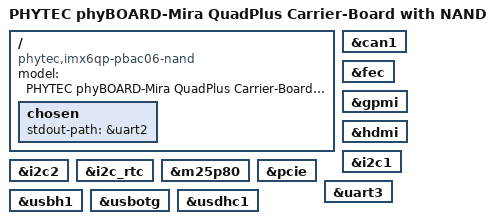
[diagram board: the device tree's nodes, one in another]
// SPDX-License-Identifier: (GPL-2.0+ OR MIT)
/*
 * Copyright (C) 2018 PHYTEC Messtechnik GmbH
 * Author: Enrico Scholz <enrico.scholz@sigma-chemnitz.de>
 */

/dts-v1/;
#include "imx6qp.dtsi"
#include "imx6qdl-phytec-phycore-som.dtsi"
#include "imx6qdl-phytec-mira.dtsi"
#include "imx6qdl-phytec-mira-peb-eval-01.dtsi"
#include "imx6qdl-phytec-mira-peb-av-02.dtsi"
#include "imx6qdl-phytec-mira-peb-wlbt-05.dtsi"

/ {
	model = "PHYTEC phyBOARD-Mira QuadPlus Carrier-Board with NAND";
	compatible = "phytec,imx6qp-pbac06-nand", "phytec,imx6qp-pbac06",
		     "phytec,imx6qdl-pcm058", "fsl,imx6qp";

	chosen {
		stdout-path = &uart2;
	};
};

&can1 {
	status = "okay";
};

&fec {
	status = "okay";
};

&gpmi {
	status = "okay";
};

&hdmi {
	status = "okay";
};

&i2c1 {
	status = "okay";
};

&i2c2 {
	status = "okay";
};

&i2c_rtc {
	status = "okay";
};

&m25p80 {
	status = "okay";
};

&pcie {
	status = "okay";
};

&uart3 {
	status = "okay";
};

&usbh1 {
	status = "okay";
};

&usbotg {
	status = "okay";
};

&usdhc1 {
	status = "okay";
};
